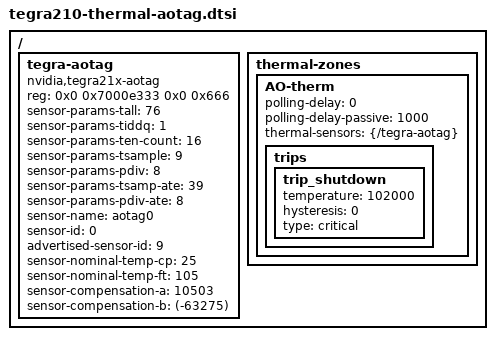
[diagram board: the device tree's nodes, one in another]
/*
 * arch/arm/boot/dts/tegra210-platforms/tegra210-thermal-aotag.dtsi
 *
 * Copyright (c) 2014, NVIDIA CORPORATION. All rights reserved.
 *
 * This program is free software; you can redistribute it and/or modify it
 * under the terms and conditions of the GNU General Public License,
 * version 2, as published by the Free Software Foundation.
 *
 * This program is distributed in the hope it will be useful, but WITHOUT
 * ANY WARRANTY; without even the implied warranty of MERCHANTABILITY or
 * FITNESS FOR A PARTICULAR PURPOSE.  See the GNU General Public License for
 * more details.
 *
 * You should have received a copy of the GNU General Public License
 * along with this program.  If not, see <http://www.gnu.org/licenses/>.
 */

/ {
	tegra-aotag {
		compatible = "nvidia,tegra21x-aotag";
		reg = <0x0 0x7000e333 0x0 0x666>;
		/*
		 * interrupts =
		 * #interrupt-names =
		 */
		status = "okay";
		sensor-params-tall       = <76>;
		sensor-params-tiddq      = <1>;
		sensor-params-ten-count  = <16>;
		sensor-params-tsample    = <9>;
		sensor-params-pdiv       = <8>;
		sensor-params-tsamp-ate  = <39>;
		sensor-params-pdiv-ate   = <8>;


		#thermal-sensor-cells = <0>;
		/* make this to '1' in case of more than one sensors */

		/*
		 * right way to do with multiple sensors is -
		 * sensor0 : sensor@<0x.....>
		 * etc.
		 * e.g,
		 * sensor@0 {
		 * sensor-name = "aotag0";
		 * sensor-id = <0>;
		 * };
		 *
		 */
		sensor-name = "aotag0";
		sensor-id = <0>;
		advertised-sensor-id = <9>;
		/*
		 * sensor-type = "nvidia,tegra21x-aotag";
		 * not required, use 'compatible' instead.
		 * keeping it as a comment
		 */
		sensor-nominal-temp-cp = <25>;
		sensor-nominal-temp-ft = <105>;

		sensor-compensation-a = <10503>;
		sensor-compensation-b = <(-63275)>;
	};
	thermal-zones {
		AO-therm {
			polling-delay = <0>;
			polling-delay-passive = <1000>;
			thermal-sensors = <&{/tegra-aotag}>;
			/* in case of multiple sensors -
			 * <&{/tegra-aotag/sensor} [0|1|..]>
			 */
			trips {
				trip_shutdown {
					temperature = <102000>;
					hysteresis = <0>;
					type = "critical";
				};
			};
		};
	};
};
